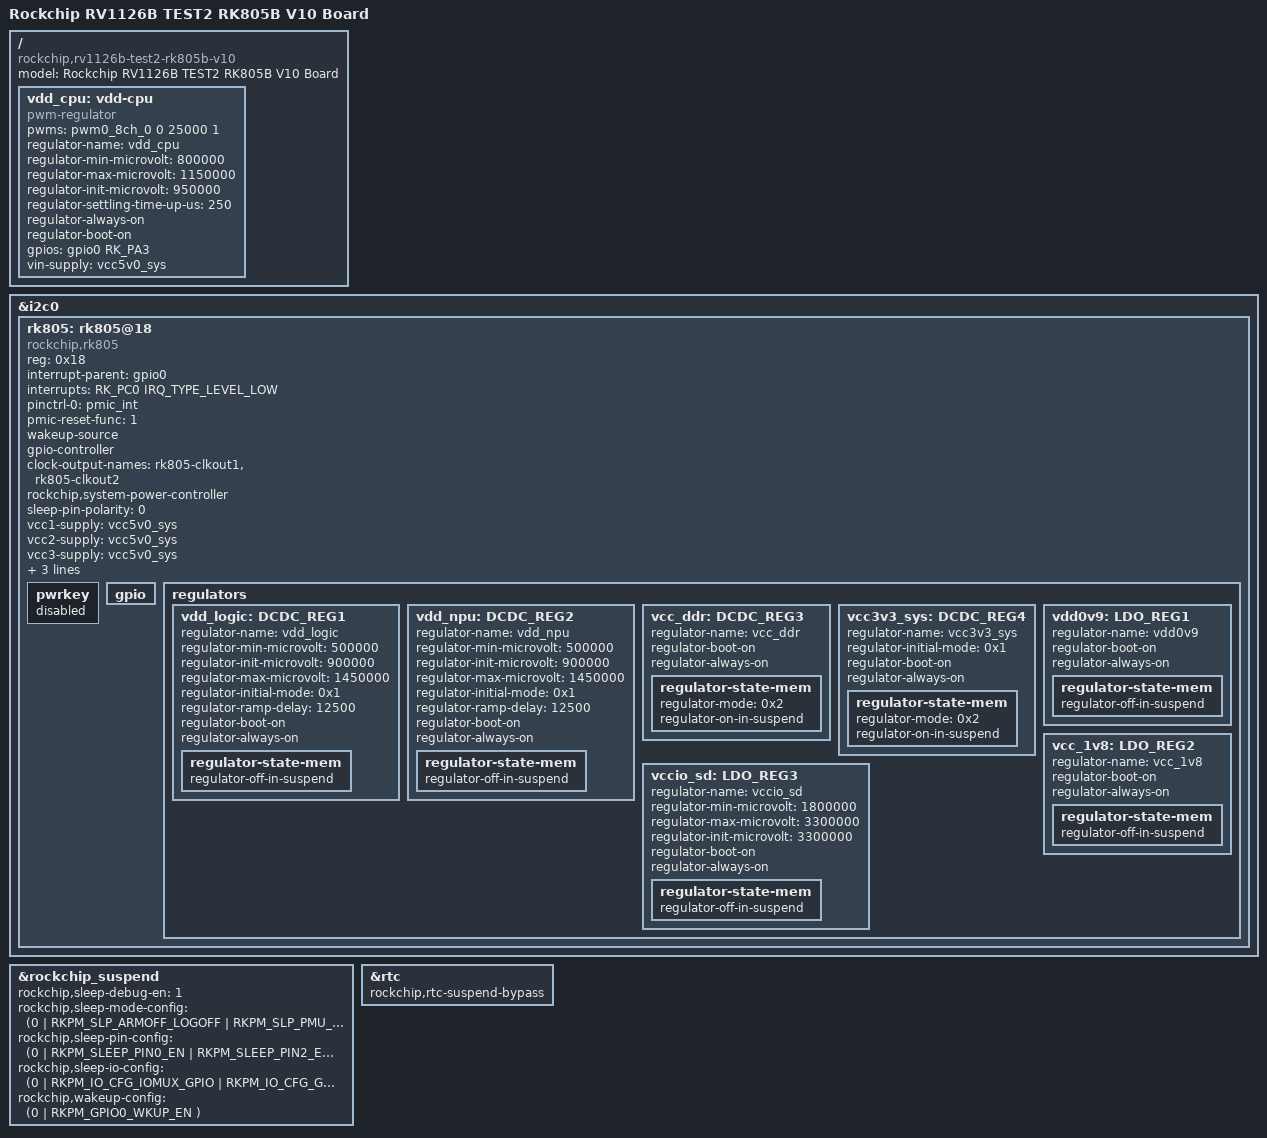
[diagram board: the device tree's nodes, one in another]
// SPDX-License-Identifier: (GPL-2.0+ OR MIT)
/*
 * Copyright (c) 2026 Rockchip Electronics Co., Ltd.
 */

/dts-v1/;
#include "rv1126b.dtsi"
#include "rv1126b-evb.dtsi"
#include "rv1126b-evb-cam-csi0.dtsi"
#include "rv1126b-evb1-v10.dtsi"

/delete-node/ &rk801;
/delete-node/ &vccio_sd;
/delete-node/ &vdd_npu;

/ {
	model = "Rockchip RV1126B TEST2 RK805B V10 Board";
	compatible = "rockchip,rv1126b-test2-rk805b-v10", "rockchip,rv1126b";

	vdd_cpu: vdd-cpu {
		compatible = "pwm-regulator";
		pwms = <&pwm0_8ch_0 0 25000 1>;
		regulator-name = "vdd_cpu";
		regulator-min-microvolt = <800000>;
		regulator-max-microvolt = <1150000>;
		regulator-init-microvolt = <950000>;
		regulator-settling-time-up-us = <250>;
		regulator-always-on;
		regulator-boot-on;
		gpios = <&gpio0 RK_PA3 GPIO_ACTIVE_HIGH>;
		vin-supply = <&vcc5v0_sys>;
	};
};

&i2c0 {
	rk805: rk805@18 {
		compatible = "rockchip,rk805";
		status = "okay";
		reg = <0x18>;
		interrupt-parent = <&gpio0>;
		interrupts = <RK_PC0 IRQ_TYPE_LEVEL_LOW>;
		pinctrl-names = "default";
		pinctrl-0 = <&pmic_int>;
		pmic-reset-func = <1>;
		wakeup-source;
		gpio-controller;
		#gpio-cells = <2>;
		#clock-cells = <1>;
		clock-output-names = "rk805-clkout1", "rk805-clkout2";
		rockchip,system-power-controller;
		sleep-pin-polarity = <0>;

		vcc1-supply = <&vcc5v0_sys>;
		vcc2-supply = <&vcc5v0_sys>;
		vcc3-supply = <&vcc5v0_sys>;
		vcc4-supply = <&vcc5v0_sys>;
		vcc5-supply = <&vcc5v0_sys>;
		vcc6-supply = <&vcc5v0_sys>;

		pwrkey {
			status = "disabled";
		};

		gpio {
			status = "okay";
		};

		regulators {
			vdd_logic: DCDC_REG1 {
				regulator-name = "vdd_logic";
				regulator-min-microvolt = <500000>;
				regulator-init-microvolt = <900000>;
				regulator-max-microvolt = <1450000>;
				regulator-initial-mode = <0x1>;
				regulator-ramp-delay = <12500>;
				regulator-boot-on;
				regulator-always-on;
				regulator-state-mem {
					regulator-off-in-suspend;
				};
			};

			vdd_npu: DCDC_REG2 {
				regulator-name = "vdd_npu";
				regulator-min-microvolt = <500000>;
				regulator-init-microvolt = <900000>;
				regulator-max-microvolt = <1450000>;
				regulator-initial-mode = <0x1>;
				regulator-ramp-delay = <12500>;
				regulator-boot-on;
				regulator-always-on;
				regulator-state-mem {
					regulator-off-in-suspend;
				};
			};

			vcc_ddr: DCDC_REG3 {
				regulator-name = "vcc_ddr";
				regulator-boot-on;
				regulator-always-on;
				regulator-state-mem {
					regulator-mode = <0x2>;
					regulator-on-in-suspend;
				};
			};

			vcc3v3_sys: DCDC_REG4 {
				regulator-name = "vcc3v3_sys";
				regulator-initial-mode = <0x1>;
				regulator-boot-on;
				regulator-always-on;
				regulator-state-mem {
					regulator-mode = <0x2>;
					regulator-on-in-suspend;
				};
			};

			vdd0v9: LDO_REG1 {
				regulator-name = "vdd0v9";
				regulator-boot-on;
				regulator-always-on;
				regulator-state-mem {
					regulator-off-in-suspend;
				};
			};

			vcc_1v8: LDO_REG2 {
				regulator-name = "vcc_1v8";
				regulator-boot-on;
				regulator-always-on;
				regulator-state-mem {
					regulator-off-in-suspend;
				};
			};

			vccio_sd: LDO_REG3 {
				regulator-name = "vccio_sd";
				regulator-min-microvolt = <1800000>;
				regulator-max-microvolt = <3300000>;
				regulator-init-microvolt = <3300000>;
				regulator-boot-on;
				regulator-always-on;
				regulator-state-mem {
					regulator-off-in-suspend;
				};
			};
		};
	};
};

&rockchip_suspend {
	status = "okay";

	rockchip,sleep-debug-en = <1>;

	rockchip,sleep-mode-config = <
		(0
		| RKPM_SLP_ARMOFF_LOGOFF
		| RKPM_SLP_PMU_PMUALIVE_32K
		| RKPM_SLP_PMU_DIS_OSC
		)
	>;

	rockchip,sleep-pin-config = <
		(0
		| RKPM_SLEEP_PIN0_EN
		| RKPM_SLEEP_PIN2_EN
		)
		(0
		| RKPM_SLEEP_PIN0_ACT_LOW
		)
	>;

	rockchip,sleep-io-config = <
		/* pmic_sleep */
		(0
		| RKPM_IO_CFG_IOMUX_GPIO
		| RKPM_IO_CFG_GPIO_DIR_INPUT
		| RKPM_IO_CFG_PULL_DOWN
		| RKPM_IO_CFG_ID(0)
		)
		(0
		| RKPM_IO_CFG_IOMUX_GPIO
		| RKPM_IO_CFG_GPIO_DIR_INPUT
		| RKPM_IO_CFG_PULL_DOWN
		| RKPM_IO_CFG_ID(2)
		)
		(0
		| RKPM_IO_CFG_PULL_NONE
		| RKPM_IO_CFG_ID(3)
		)
		(0
		| RKPM_IO_CFG_IOMUX_GPIO
		| RKPM_IO_CFG_GPIO_DIR_INPUT
		| RKPM_IO_CFG_PULL_DOWN
		| RKPM_IO_CFG_ID(4)
		)
		(0
		| RKPM_IO_CFG_IOMUX_GPIO
		| RKPM_IO_CFG_GPIO_DIR_INPUT
		| RKPM_IO_CFG_PULL_UP
		| RKPM_IO_CFG_ID(5)
		)
		(0
		| RKPM_IO_CFG_IOMUX_GPIO
		| RKPM_IO_CFG_GPIO_DIR_INPUT
		| RKPM_IO_CFG_PULL_DOWN
		| RKPM_IO_CFG_ID(6)
		)
		(0
		| RKPM_IO_CFG_IOMUX_GPIO
		| RKPM_IO_CFG_GPIO_DIR_INPUT
		| RKPM_IO_CFG_PULL_UP
		| RKPM_IO_CFG_ID(7)
		)
		(0
		| RKPM_IO_CFG_IOMUX_GPIO
		| RKPM_IO_CFG_GPIO_DIR_INPUT
		| RKPM_IO_CFG_PULL_DOWN
		| RKPM_IO_CFG_ID(8)
		)
		(0
		| RKPM_IO_CFG_IOMUX_GPIO
		| RKPM_IO_CFG_GPIO_DIR_INPUT
		| RKPM_IO_CFG_PULL_DOWN
		| RKPM_IO_CFG_ID(9)
		)
		(0
		| RKPM_IO_CFG_IOMUX_GPIO
		| RKPM_IO_CFG_GPIO_DIR_INPUT
		| RKPM_IO_CFG_PULL_DOWN
		| RKPM_IO_CFG_ID(10)
		)
		(0
		| RKPM_IO_CFG_IOMUX_GPIO
		| RKPM_IO_CFG_GPIO_DIR_INPUT
		| RKPM_IO_CFG_PULL_DOWN
		| RKPM_IO_CFG_ID(11)
		)
		(0
		| RKPM_IO_CFG_IOMUX_GPIO
		| RKPM_IO_CFG_GPIO_DIR_INPUT
		| RKPM_IO_CFG_PULL_DOWN
		| RKPM_IO_CFG_ID(12)
		)
		(0
		| RKPM_IO_CFG_IOMUX_GPIO
		| RKPM_IO_CFG_GPIO_DIR_INPUT
		| RKPM_IO_CFG_PULL_DOWN
		| RKPM_IO_CFG_ID(20)
		)
		(0
		| RKPM_IO_CFG_IOMUX_GPIO
		| RKPM_IO_CFG_GPIO_DIR_INPUT
		| RKPM_IO_CFG_PULL_DOWN
		| RKPM_IO_CFG_ID(21)
		)
		(0
		| RKPM_IO_CFG_IOMUX_GPIO
		| RKPM_IO_CFG_GPIO_DIR_INPUT
		| RKPM_IO_CFG_PULL_DOWN
		| RKPM_IO_CFG_ID(22)
		)
		(0
		| RKPM_IO_CFG_IOMUX_GPIO
		| RKPM_IO_CFG_GPIO_DIR_INPUT
		| RKPM_IO_CFG_PULL_DOWN
		| RKPM_IO_CFG_ID(23)
		)
		(0
		| RKPM_IO_CFG_IOMUX_GPIO
		| RKPM_IO_CFG_GPIO_DIR_INPUT
		| RKPM_IO_CFG_PULL_DOWN
		| RKPM_IO_CFG_ID(24)
		)
		(0
		| RKPM_IO_CFG_IOMUX_GPIO
		| RKPM_IO_CFG_GPIO_DIR_INPUT
		| RKPM_IO_CFG_PULL_DOWN
		| RKPM_IO_CFG_ID(25)
		)
	>;

	rockchip,wakeup-config = <
		(0
		| RKPM_GPIO0_WKUP_EN
		)
	>;
};

&rtc {
	rockchip,rtc-suspend-bypass;
	status = "okay";
};
